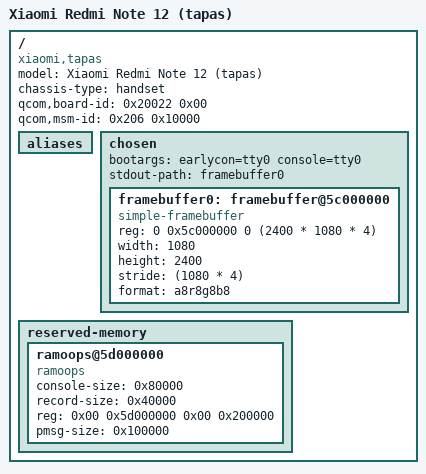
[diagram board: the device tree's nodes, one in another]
/dts-v1/;

#include "sm6225.dtsi"

/ {
    model = "Xiaomi Redmi Note 12 (tapas)";
    compatible = "xiaomi,tapas", "qcom,khaje";
	chassis-type = "handset";

	qcom,board-id = <0x20022 0x00>;
	qcom,msm-id = <0x206 0x10000>;
	
    aliases {
	};

	chosen {
		bootargs = "earlycon=tty0 console=tty0";

		#address-cells = <2>;
		#size-cells = <2>;
		ranges;

        stdout-path = "framebuffer0";

        framebuffer0: framebuffer@5c000000 {
			compatible = "simple-framebuffer";
			reg = <0 0x5c000000 0 (2400 * 1080 * 4)>;
			width = <1080>;
			height = <2400>;
			stride = <(1080 * 4)>;
			format = "a8r8g8b8";
			status= "okay";
		};
	};

    reserved-memory {
        ramoops@5d000000 {
			console-size = <0x80000>;
			record-size = <0x40000>;
			reg = <0x00 0x5d000000 0x00 0x200000>;
			pmsg-size = <0x100000>;
			compatible = "ramoops";
		};
    };
};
